# GPMC_TARG register map
Vendor: Texas Instruments
Peripheral module from a debugger description file (folder DRA74xP_75xP_76xP_77xP).
Registers are 32-bit, read-only, reset 0x0 unless marked. A register's access mark holds for its fields unless they carry their own. Offsets are as the file gives them; lines under a group give offsets from that group; [hi:lo] are bit positions; {n}, {i} and the like mark numbered series; 'fields as' and 'values as' point back to an identical list; <NAME> marks a mode.

## GPMC_TARG
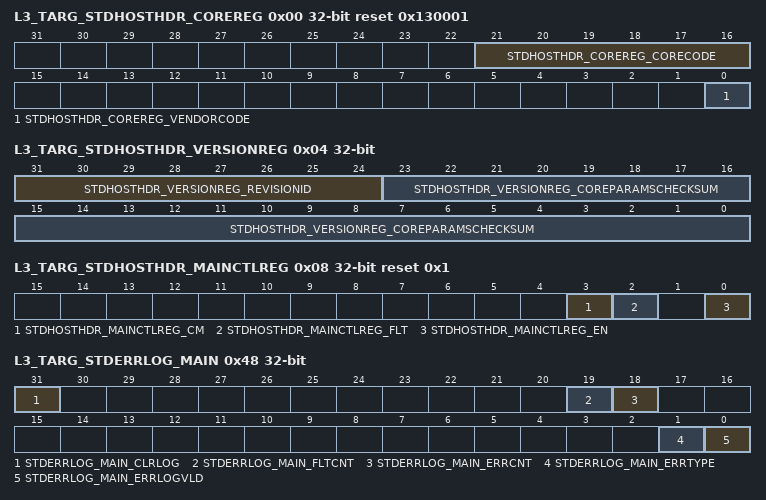
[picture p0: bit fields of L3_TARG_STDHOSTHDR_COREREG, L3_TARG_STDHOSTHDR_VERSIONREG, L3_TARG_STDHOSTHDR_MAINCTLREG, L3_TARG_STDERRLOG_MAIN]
0x00 L3_TARG_STDHOSTHDR_COREREG reset 0x130001
  [21:16] STDHOSTHDR_COREREG_CORECODE — The Core Code field is a constant reporting a vendor-specific core generator code. Type: Constant. Reset value: 0x13.
  [0] STDHOSTHDR_COREREG_VENDORCODE — The Vendor Code field is a constant reporting the core generator vendor code. Type: Constant. Reset value: 0x1.
    0=Third-party_vendor; 1=STDHOSTHDR_COREREG_VENDORCODE_1_r
0x04 L3_TARG_STDHOSTHDR_VERSIONREG
  [31:24] STDHOSTHDR_VERSIONREG_REVISIONID — The Revision Identifier field is a constant reporting the core generator revision number. Type: Constant. Reset value: 0x0.
  [23:0] STDHOSTHDR_VERSIONREG_COREPARAMSCHECKSUM — Reserved. Type: Reserved. Reset value: Reserved.
0x08 L3_TARG_STDHOSTHDR_MAINCTLREG access per field reset 0x1
  [3] STDHOSTHDR_MAINCTLREG_CM ro — Reserved for internal testing. Must be set to 0. Type: Control. Reset value: 0x0.
  [2] STDHOSTHDR_MAINCTLREG_FLT ro — Asserted when a Fault condition is detected: if the unit includes Error Logging, Flt is asserted when the FltCnt register field indicates a Fault, and deasserted when FltCnt is reset. If no Error Logging is implemented, this bit becomes unit-dependent. In all cases, Flt bit and Flt pin (service network) have the same logical level. Type: Status. Reset value: X.
  [0] STDHOSTHDR_MAINCTLREG_EN rw — Sets the global core enable. Note: A disabled master does not generate any NTTP requests, and a disabled slave replies with an error packet to any request it receives. Type: Control. Reset value: 0x1.
0x10 L3_TARG_STDHOSTHDR_NTTPADDR_0 (reset mask 0xFFFFFF80)
  [6:0] STDHOSTHDR_NTTPADDR_0 — Shows the Rx port address. Type: Control. Reset value: 0x15.
0x40 L3_TARG_STDERRLOG_SVRTSTDLVL access per field reset 0x2
  [1:0] STDERRLOG_SVRTSTDLVL_0 rw — Severity level parameters Type: Control. Reset value: 0x2.
    0=disabled (Error logging is disabled.); 1=Errors are logged with severity level Error; 2=fault (Errors are logged with severity level Fault.)
0x44 L3_TARG_STDERRLOG_SVRTCUSTOMLVL access per field reset 0x2
  [1:0] STDERRLOG_SVRTCUSTOMLVL_0 rw — Severity level parameters Type: Control. Reset value: 0x2.
    values as L3_TARG_STDERRLOG_SVRTSTDLVL.STDERRLOG_SVRTSTDLVL_0
0x48 L3_TARG_STDERRLOG_MAIN access per field
  [31] STDERRLOG_MAIN_CLRLOG rw — Clears 'Error Logging Valid' bit when written to 1. Type: Give_AutoCleared. Reset value: 0x0.
  [19] STDERRLOG_MAIN_FLTCNT rw — Asserted when at least one error with severity level FAULT is detected. Reset when written to 1. Type: Take. Reset value: 0x0.
  [18] STDERRLOG_MAIN_ERRCNT rw — Asserted when at least one error with severity level ERROR is detected. Reset when written to 1. Type: Take. Reset value: 0x0.
  [1] STDERRLOG_MAIN_ERRTYPE ro — Indicates logging type. Type: Status. Reset value: X.
    0=standard (Logged Error format is standard (header and necker recorded).); 1=module dependent (Logged Error format is module dependent. CustomInfo register(s) may be implemented to store additional information.)
  [0] STDERRLOG_MAIN_ERRLOGVLD ro — Error Logging Valid. Asserted when logging information is valid(indicates that an error has been logged). Type: Status. Reset value: X.
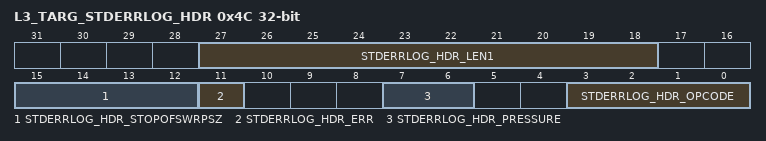
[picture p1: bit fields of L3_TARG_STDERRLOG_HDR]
0x4C L3_TARG_STDERRLOG_HDR
  [27:18] STDERRLOG_HDR_LEN1 — This field contains the number of payload cell(s) minus one of the logged packet. Type: Status. Reset value: X.
  [15:12] STDERRLOG_HDR_STOPOFSWRPSZ — StopOfs or WrapSize field of the logged packet (meaning depends on Wrp bit of logged opcode). Type: Status. Reset value: X.
  [11] STDERRLOG_HDR_ERR — Err bit of the logged packet. Type: Status. Reset value: X.
  [7:6] STDERRLOG_HDR_PRESSURE — Pressure field of the logged packet. Type: Status. Reset value: X.
  [3:0] STDERRLOG_HDR_OPCODE — Opcode of the logged packet. Type: Status. Reset value: X. 0x0: Store without acknowledge, incrementing burst, non-atomic request 0x1: Store without acknowledge, wrapping burst, non-atomic request 0x2: Store with acknowledge, incrementing burst, non-atomic request 0x3: Store with acknowledge, wrapping burst, non-atomic request 0x4: Load, incrementing burst, non-atomic request 0x5: Load, wrapping burst, non-atomic request 0x6: Control packet 0x7: Flush 0x8: Store without acknowledge, incrementing burst, atomic request 0x9: Store without acknowledge, wrapping burst, atomic request 0xA: Store with acknowledge, incrementing burst, atomic request 0xB: Store with acknowledge, wrapping burst, atomic request 0xC: Load, incrementing burst, atomic request 0xD: Load, wrapping burst, atomic request 0xE: Reserved 0xF: Reserved
0x50 L3_TARG_STDERRLOG_MSTADDR
  [7:0] STDERRLOG_MSTADDR — Master Address field of the logged packet. Type: Status. Reset value: X.
0x54 L3_TARG_STDERRLOG_SLVADDR
  [6:0] STDERRLOG_SLVADDR — Slave Address field of the logged packet. Type: Status. Reset value: X.
0x58 L3_TARG_STDERRLOG_INFO
  [7:0] STDERRLOG_INFO — Info field of the logged packet. Type: Status. Reset value: X.
0x5C L3_TARG_STDERRLOG_SLVOFSLSB
  [31:0] STDERRLOG_SLVOFSLSB — LSB of the 'slave offset' field, concatenated with 'start offset' field of the logged packet. Type: Status. Reset value: X.
0x60 L3_TARG_STDERRLOG_SLVOFSMSB
  [0] STDERRLOG_SLVOFSMSB — MSB of the 'slave offset' field of the logged packet (according to NTTP packet format, this register field may exceed the actual 'slave offset' size. Unused bits are stuck at 0, if any). Type: Status. Reset value: X.
0x64 L3_TARG_STDERRLOG_CUSTOMINFO_INFO
  [7:0] STDERRLOG_CUSTOMINFO_INFO — Info field of the response packet. Type: Status. Reset value: X.
0x68 L3_TARG_STDERRLOG_CUSTOMINFO_MSTADDR
  [7:0] STDERRLOG_CUSTOMINFO_MSTADDR — MstAddr field of the response packet. Type: Status. Reset value: X.
0x6C L3_TARG_STDERRLOG_CUSTOMINFO_OPCODE
  [1:0] STDERRLOG_CUSTOMINFO_OPCODE — Opcode of the response packet. Type: Status. Reset value: X. 0x0: Logged request is 0x1: Logged request is 0x2: Logged request is 0x3: Reserved
0x80 L3_TARG_ADDRSPACESIZELOG access per field reset 0x1F
  [4:0] ADDRSPACESIZELOG rw — The address space size is equal to 2**AddrSpaceSizeLog * 4K in bytes. Type: Control. Reset value: 0x1F.
